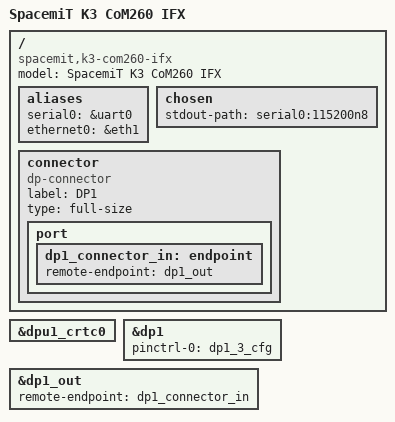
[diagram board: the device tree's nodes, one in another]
// SPDX-License-Identifier: (GPL-2.0 OR MIT)
/*
 * Copyright (c) 2026 SpacemiT (Hangzhou) Technology Co. Ltd
 * Copyright (c) 2026 Yixun Lan <dlan@kernel.org>
 */

#include "k3-com260.dtsi"
#include "k3-display.dtsi"

/ {
	model = "SpacemiT K3 CoM260 IFX";
	compatible = "spacemit,k3-com260-ifx", "spacemit,k3-com260", "spacemit,k3";

	aliases {
		serial0 = &uart0;
		ethernet0 = &eth1;
	};

	chosen {
		stdout-path = "serial0:115200n8";
	};

	connector {
		compatible = "dp-connector";
		label = "DP1";
		type = "full-size";

		port {
			dp1_connector_in: endpoint {
				remote-endpoint = <&dp1_out>;
			};
		};
	};
};

&dpu1_crtc0 {
	status = "okay";
};

&dp1 {
	pinctrl-names = "default";
	pinctrl-0 = <&dp1_3_cfg>;
	status = "okay";
};

&dp1_out {
	remote-endpoint = <&dp1_connector_in>;
};
